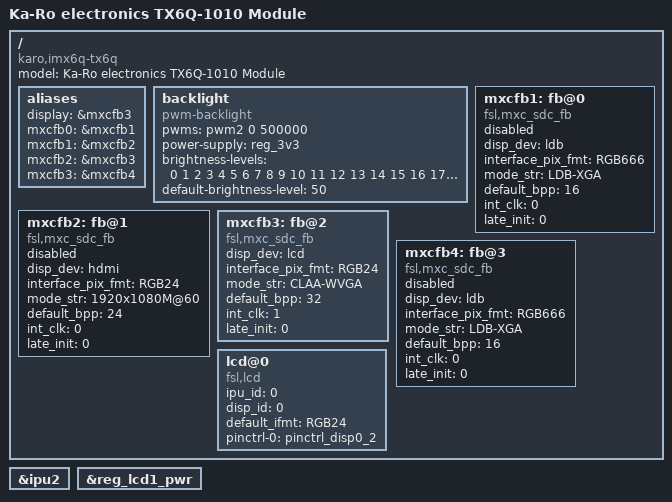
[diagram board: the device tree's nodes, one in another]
/*
 * Copyright 2014 Lothar Waßmann <LW@KARO-electronics.de>
 *
 * The code contained herein is licensed under the GNU General Public
 * License. You may obtain a copy of the GNU General Public License
 * Version 2 at the following locations:
 *
 * http://www.opensource.org/licenses/gpl-license.html
 * http://www.gnu.org/copyleft/gpl.html
 */

/dts-v1/;
#include "imx6q.dtsi"
#include "imx6qdl-tx6.dtsi"

/ {
	model = "Ka-Ro electronics TX6Q-1010 Module";
	compatible = "karo,imx6q-tx6q", "fsl,imx6q";

	aliases {
		display = &mxcfb3;
		mxcfb0 = &mxcfb1;
		mxcfb1 = &mxcfb2;
		mxcfb2 = &mxcfb3;
		mxcfb3 = &mxcfb4;
	};

	backlight: backlight {
		compatible = "pwm-backlight";
		pwms = <&pwm2 0 500000>;
		power-supply = <&reg_3v3>;
		/*
		 * a poor man's way to create a 1:1 relationship between
		 * the PWM value and the actual duty cycle
		 */
		brightness-levels = < 0  1  2  3  4  5  6  7  8  9
				     10 11 12 13 14 15 16 17 18 19
				     20 21 22 23 24 25 26 27 28 29
				     30 31 32 33 34 35 36 37 38 39
				     40 41 42 43 44 45 46 47 48 49
				     50 51 52 53 54 55 56 57 58 59
				     60 61 62 63 64 65 66 67 68 69
				     70 71 72 73 74 75 76 77 78 79
				     80 81 82 83 84 85 86 87 88 89
				     90 91 92 93 94 95 96 97 98 99
				    100>;
		default-brightness-level = <50>;
        };

	mxcfb1: fb@0 {
		compatible = "fsl,mxc_sdc_fb";
		disp_dev = "ldb";
		interface_pix_fmt = "RGB666";
		mode_str ="LDB-XGA";
		default_bpp = <16>;
		int_clk = <0>;
		late_init = <0>;
		status = "disabled";
	};

	mxcfb2: fb@1 {
		compatible = "fsl,mxc_sdc_fb";
		disp_dev = "hdmi";
		interface_pix_fmt = "RGB24";
		mode_str ="1920x1080M@60";
		default_bpp = <24>;
		int_clk = <0>;
		late_init = <0>;
		status = "disabled";
	};

	mxcfb3: fb@2 {
		compatible = "fsl,mxc_sdc_fb";
		disp_dev = "lcd";
		interface_pix_fmt = "RGB24";
		mode_str ="CLAA-WVGA";
		default_bpp = <32>;
		int_clk = <1>;
		late_init = <0>;
		status = "okay";
	};

	mxcfb4: fb@3 {
		compatible = "fsl,mxc_sdc_fb";
		disp_dev = "ldb";
		interface_pix_fmt = "RGB666";
		mode_str ="LDB-XGA";
		default_bpp = <16>;
		int_clk = <0>;
		late_init = <0>;
		status = "disabled";
	};

	lcd@0 {
		compatible = "fsl,lcd";
		ipu_id = <0>;
		disp_id = <0>;
		default_ifmt = "RGB24";
		pinctrl-names = "default";
		pinctrl-0 = <&pinctrl_disp0_2>;
		status = "okay";
	};
};

&ipu2 {
//	status = "disabled";
};

&reg_lcd1_pwr {
	status = "okay";
};
